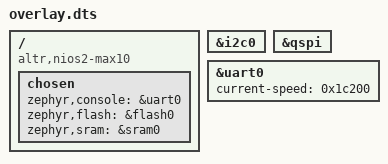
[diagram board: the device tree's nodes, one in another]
/ {
	compatible = "altr,nios2-max10";
	chosen {
		zephyr,console = &uart0;
		zephyr,flash = &flash0;
		zephyr,sram = &sram0;
	};
};
&i2c0{
	status = "okay";
};
&qspi{
	status = "okay";
};
&uart0{
	status = "okay";
	current-speed = < 0x1c200 >;
};
